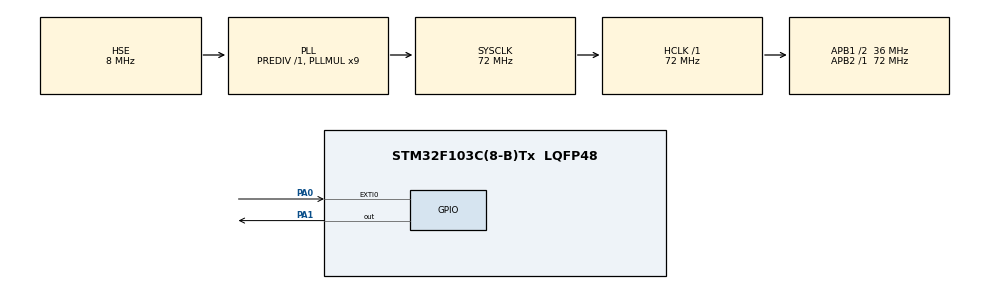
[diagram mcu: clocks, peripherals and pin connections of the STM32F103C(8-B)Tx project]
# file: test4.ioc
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Mcu.Family=STM32F1
Mcu.Name=STM32F103C(8-B)Tx
Mcu.Package=LQFP48
NVIC.EXTI0_IRQn=true\:0\:0\:false\:false\:true\:true\:true\:true
NVIC.PriorityGroup=NVIC_PRIORITYGROUP_4
NVIC.TIM2_IRQn=true\:0\:0\:false\:false\:true\:true\:true\:true
PA0-WKUP.GPIO_ModeDefaultEXTI=GPIO_MODE_IT_RISING_FALLING
PA0-WKUP.GPIO_PuPd=GPIO_PULLUP
PA0-WKUP.Signal=GPXTI0
PA1.GPIO_PuPd=GPIO_PULLDOWN
PA1.Signal=GPIO_Output
PA13.Mode=Serial_Wire
PA13.Signal=SYS_JTMS-SWDIO
PA14.Mode=Serial_Wire
PA14.Signal=SYS_JTCK-SWCLK
PD0-OSC_IN.Mode=HSE-External-Oscillator
PD0-OSC_IN.Signal=RCC_OSC_IN
PD1-OSC_OUT.Mode=HSE-External-Oscillator
PD1-OSC_OUT.Signal=RCC_OSC_OUT
ProjectManager.HeapSize=0x200
ProjectManager.StackSize=0x400
ProjectManager.TargetToolchain=MDK-ARM V5.32
RCC.AHBFreq_Value=72000000
RCC.APB1CLKDivider=RCC_HCLK_DIV2
RCC.APB1Freq_Value=36000000
RCC.APB1TimFreq_Value=72000000
RCC.APB2Freq_Value=72000000
RCC.APB2TimFreq_Value=72000000
RCC.HCLKFreq_Value=72000000
RCC.PLLMUL=RCC_PLL_MUL9
RCC.PLLSourceVirtual=RCC_PLLSOURCE_HSE
RCC.SYSCLKFreq_VALUE=72000000
RCC.SYSCLKSource=RCC_SYSCLKSOURCE_PLLCLK
RCC.USBFreq_Value=72000000
TIM2.Period=9
TIM2.Prescaler=7199
VP_TIM2_VS_ClockSourceINT.Mode=Internal
board=custom

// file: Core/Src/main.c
/* USER CODE BEGIN Header */
/**
  ******************************************************************************
  * @file           : main.c
  * @brief          : Main program body
  ******************************************************************************
  * @attention
  *
  * Copyright (c) 2026 STMicroelectronics.
  * All rights reserved.
  *
  * This software is licensed under terms that can be found in the LICENSE file
  * in the root directory of this software component.
  * If no LICENSE file comes with this software, it is provided AS-IS.
  *
  ******************************************************************************
  */
/* USER CODE END Header */
#include "main.h"

TIM_HandleTypeDef htim2;

/* USER CODE BEGIN PV */
volatile uint32_t tim2_ms=0U;//时间
volatile uint32_t led_mode=0;//led的模式 0为灭 1为亮 2为闪
uint32_t press_start=0;//按住的起始时刻
uint32_t led_mode0=0;//led上次的模式
/* USER CODE END PV */

void SystemClock_Config(void);
static void MX_GPIO_Init(void);
static void MX_TIM2_Init(void);

/* USER CODE BEGIN 0 */
void HAL_GPIO_EXTI_Callback(uint16_t GPIO_Pin)
{
	static uint32_t last_tick=0;//最后一次改变的时间
	static uint8_t first_press=1;//判断是否第一次按下
	static uint8_t pressed=0;//判断是否持续按压
	if(GPIO_Pin!=GPIO_PIN_0)
	{
		return;
	}//只存在一个按键时，可不加
	uint32_t now=tim2_ms;
	if(!first_press&&(uint32_t)(now-last_tick)<20)//消抖
	{
		return;
	}
	first_press=0;//已经按了第一次
	last_tick=now;
	if(HAL_GPIO_ReadPin(GPIOA,GPIO_PIN_0)==GPIO_PIN_SET)//判断PA0引脚是否为高电平，高电平则为松手，则进入循环,开始判断按了多少秒
	{
		if((now-press_start)>=1000)//进入或退出快闪阶段
		{
				if(led_mode==2)//退出
				{
					led_mode=led_mode0;
				}
				else//进入
				{
					led_mode0=led_mode;
					led_mode=2;
				}
		}
		else//快闪时不变，常亮或者常灭时反转
		{
			if(led_mode!=2)
			{
				led_mode=!led_mode;
			}
		}
		pressed=0;
		return;
	}
	if(pressed)//按下之后不松手，且抖动结束
	{
		return;
	}
	pressed=1;
	press_start=tim2_ms;//按按键的起始时间
	//led_mode=!led_mode;
}

/* USER CODE END 0 */

int main(void)
{

  /* MCU Configuration--------------------------------------------------------*/

  /* Reset of all peripherals, Initializes the Flash interface and the Systick. */
  HAL_Init();

  /* Configure the system clock */
  SystemClock_Config();

  /* Initialize all configured peripherals */
  MX_GPIO_Init();
  MX_TIM2_Init();
  /* USER CODE BEGIN 2 */
	HAL_TIM_Base_Start_IT(&htim2);

  /* USER CODE END 2 */

  /* Infinite loop */
  /* USER CODE BEGIN WHILE */
  while (1)
  {
		if(led_mode==1)
		{
			HAL_GPIO_WritePin(GPIOA,GPIO_PIN_1,GPIO_PIN_SET);//亮
		}
		if(led_mode==0)
			HAL_GPIO_WritePin(GPIOA,GPIO_PIN_1,GPIO_PIN_RESET);//暗
    /* USER CODE END WHILE */

  }
}

void SystemClock_Config(void)
{
  RCC_OscInitTypeDef RCC_OscInitStruct = {0};
  RCC_ClkInitTypeDef RCC_ClkInitStruct = {0};

  /** Initializes the RCC Oscillators according to the specified parameters
  * in the RCC_OscInitTypeDef structure.
  */
  RCC_OscInitStruct.OscillatorType = RCC_OSCILLATORTYPE_HSE;
  RCC_OscInitStruct.HSEState = RCC_HSE_ON;
  RCC_OscInitStruct.HSEPredivValue = RCC_HSE_PREDIV_DIV1;
  RCC_OscInitStruct.HSIState = RCC_HSI_ON;
  RCC_OscInitStruct.PLL.PLLState = RCC_PLL_ON;
  RCC_OscInitStruct.PLL.PLLSource = RCC_PLLSOURCE_HSE;
  RCC_OscInitStruct.PLL.PLLMUL = RCC_PLL_MUL9;
  if (HAL_RCC_OscConfig(&RCC_OscInitStruct) != HAL_OK)
  {
    Error_Handler();
  }

  /** Initializes the CPU, AHB and APB buses clocks
  */
  RCC_ClkInitStruct.ClockType = RCC_CLOCKTYPE_HCLK|RCC_CLOCKTYPE_SYSCLK
                              |RCC_CLOCKTYPE_PCLK1|RCC_CLOCKTYPE_PCLK2;
  RCC_ClkInitStruct.SYSCLKSource = RCC_SYSCLKSOURCE_PLLCLK;
  RCC_ClkInitStruct.AHBCLKDivider = RCC_SYSCLK_DIV1;
  RCC_ClkInitStruct.APB1CLKDivider = RCC_HCLK_DIV2;
  RCC_ClkInitStruct.APB2CLKDivider = RCC_HCLK_DIV1;

  if (HAL_RCC_ClockConfig(&RCC_ClkInitStruct, FLASH_LATENCY_2) != HAL_OK)
  {
    Error_Handler();
  }
}

static void MX_TIM2_Init(void)
{

  TIM_ClockConfigTypeDef sClockSourceConfig = {0};
  TIM_MasterConfigTypeDef sMasterConfig = {0};

  htim2.Instance = TIM2;
  htim2.Init.Prescaler = 7199;
  htim2.Init.CounterMode = TIM_COUNTERMODE_UP;
  htim2.Init.Period = 9;
  htim2.Init.ClockDivision = TIM_CLOCKDIVISION_DIV1;
  htim2.Init.AutoReloadPreload = TIM_AUTORELOAD_PRELOAD_DISABLE;
  if (HAL_TIM_Base_Init(&htim2) != HAL_OK)
  {
    Error_Handler();
  }
  sClockSourceConfig.ClockSource = TIM_CLOCKSOURCE_INTERNAL;
  if (HAL_TIM_ConfigClockSource(&htim2, &sClockSourceConfig) != HAL_OK)
  {
    Error_Handler();
  }
  sMasterConfig.MasterOutputTrigger = TIM_TRGO_RESET;
  sMasterConfig.MasterSlaveMode = TIM_MASTERSLAVEMODE_DISABLE;
  if (HAL_TIMEx_MasterConfigSynchronization(&htim2, &sMasterConfig) != HAL_OK)
  {
    Error_Handler();
  }

}

static void MX_GPIO_Init(void)
{
  GPIO_InitTypeDef GPIO_InitStruct = {0};

  /* GPIO Ports Clock Enable */
  __HAL_RCC_GPIOD_CLK_ENABLE();
  __HAL_RCC_GPIOA_CLK_ENABLE();

  /*Configure GPIO pin Output Level */
  HAL_GPIO_WritePin(GPIOA, GPIO_PIN_1, GPIO_PIN_RESET);

  /*Configure GPIO pin : PA0 */
  GPIO_InitStruct.Pin = GPIO_PIN_0;
  GPIO_InitStruct.Mode = GPIO_MODE_IT_RISING_FALLING;
  GPIO_InitStruct.Pull = GPIO_PULLUP;
  HAL_GPIO_Init(GPIOA, &GPIO_InitStruct);

  /*Configure GPIO pin : PA1 */
  GPIO_InitStruct.Pin = GPIO_PIN_1;
  GPIO_InitStruct.Mode = GPIO_MODE_OUTPUT_PP;
  GPIO_InitStruct.Pull = GPIO_PULLDOWN;
  GPIO_InitStruct.Speed = GPIO_SPEED_FREQ_LOW;
  HAL_GPIO_Init(GPIOA, &GPIO_InitStruct);

  /* EXTI interrupt init*/
  HAL_NVIC_SetPriority(EXTI0_IRQn, 0, 0);
  HAL_NVIC_EnableIRQ(EXTI0_IRQn);

}

/* USER CODE BEGIN 4 */
void HAL_TIM_PeriodElapsedCallback(TIM_HandleTypeDef *htim)
{
	if(htim==&htim2)
	{
		tim2_ms++;
		static uint32_t count=0;
		count++;//每1ms加1
		if(count>=100)//每100ms反转一次电平 周期为200ms 频率即为5hz
		{
			count=0;
			if(led_mode==2)
			{
				HAL_GPIO_TogglePin(GPIOA,GPIO_PIN_1);
			}
		}
	}
}

/* USER CODE END 4 */

void Error_Handler(void)
{
  __disable_irq();
  while (1)
  {
  }
}
